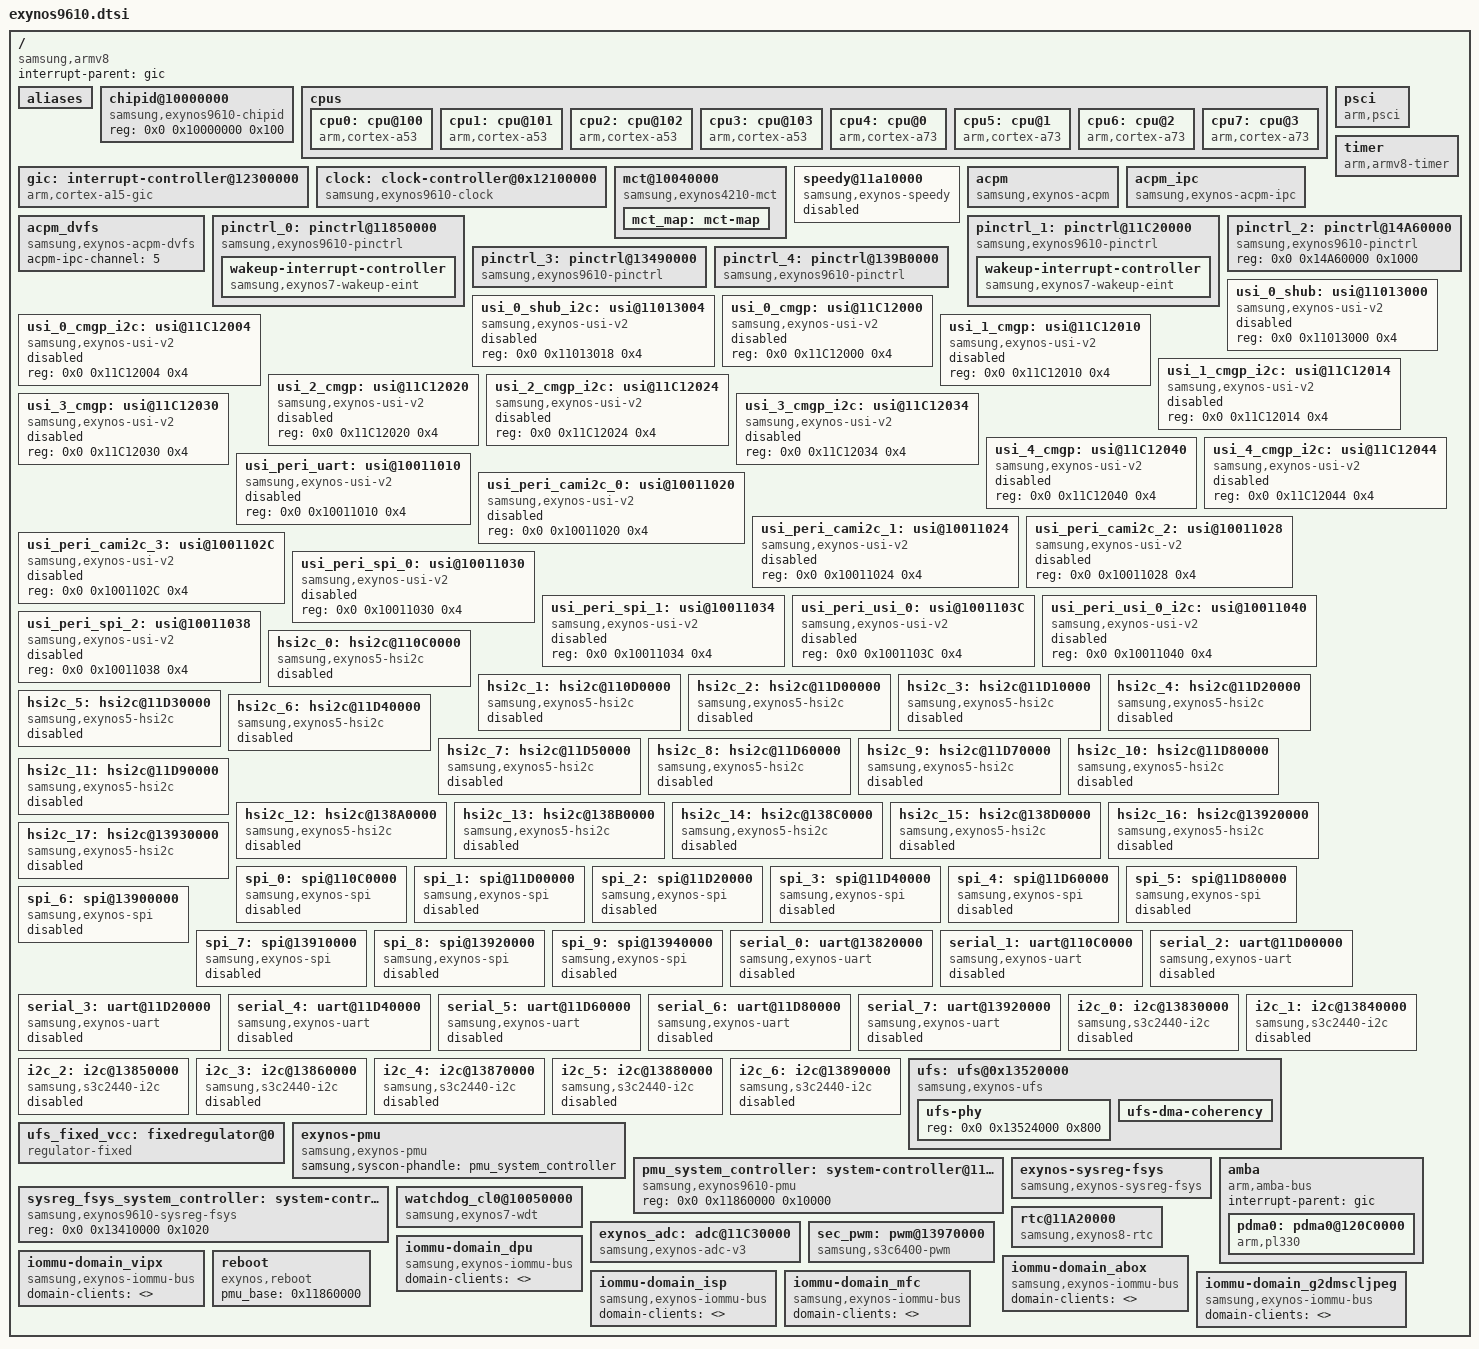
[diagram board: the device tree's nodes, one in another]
/*
 * SAMSUNG EXYNOS9610 SoC device tree source
 *
 * Copyright (c) 2017 Samsung Electronics Co., Ltd.
 *		http://www.samsung.com
 *
 * SAMSUNG EXYNOS9610 SoC device nodes are listed in this file.
 * EXYNOS9610 based board files can include this file and provide
 * values for board specfic bindings.
 *
 * This program is free software; you can redistribute it and/or modify
 * it under the terms of the GNU General Public License version 2 as
 * published by the Free Software Foundation.
 */

#include <dt-bindings/clock/exynos9610.h>
#include <dt-bindings/interrupt-controller/arm-gic.h>
#include "exynos9610-pinctrl.dtsi"
#include <dt-bindings/ufs/ufs.h>
#include "exynos9610-sysmmu.dtsi"

/ {
	compatible = "samsung,armv8", "samsung,exynos9610";
	interrupt-parent = <&gic>;
	#address-cells = <2>;
	#size-cells = <1>;

	aliases {
		pinctrl0 = &pinctrl_0;
		pinctrl1 = &pinctrl_1;
		pinctrl2 = &pinctrl_2;
		pinctrl3 = &pinctrl_3;
		pinctrl4 = &pinctrl_4;
//		pinctrl5 = &pinctrl_5;
		usi0 = &usi_0_shub;
		usi1 = &usi_0_shub_i2c;
		usi2 = &usi_0_cmgp;
		usi3 = &usi_0_cmgp_i2c;
		usi4 = &usi_1_cmgp;
		usi5 = &usi_1_cmgp_i2c;
		usi6 = &usi_2_cmgp;
		usi7 = &usi_2_cmgp_i2c;
		usi8 = &usi_3_cmgp;
		usi9 = &usi_3_cmgp_i2c;
		usi10 = &usi_4_cmgp;
		usi11 = &usi_4_cmgp_i2c;
		usi12 = &usi_peri_uart;
		usi13 = &usi_peri_cami2c_0;
		usi14 = &usi_peri_cami2c_1;
		usi15 = &usi_peri_cami2c_2;
		usi16 = &usi_peri_cami2c_3;
		usi17 = &usi_peri_spi_0;
		usi18 = &usi_peri_spi_1;
		usi19 = &usi_peri_usi_0;
		usi20 = &usi_peri_usi_0_i2c;
		usi21 = &usi_peri_spi_2;
		hsi2c0 = &hsi2c_0;
		hsi2c1 = &hsi2c_1;
		hsi2c2 = &hsi2c_2;
		hsi2c3 = &hsi2c_3;
		hsi2c4 = &hsi2c_4;
		hsi2c5 = &hsi2c_5;
		hsi2c6 = &hsi2c_6;
		hsi2c7 = &hsi2c_7;
		hsi2c8 = &hsi2c_8;
		hsi2c9 = &hsi2c_9;
		hsi2c10 = &hsi2c_10;
		hsi2c11 = &hsi2c_11;
		hsi2c12 = &hsi2c_12;
		hsi2c13 = &hsi2c_13;
		hsi2c14 = &hsi2c_14;
		hsi2c15 = &hsi2c_15;
		hsi2c16 = &hsi2c_16;
		hsi2c17 = &hsi2c_17;
		spi0 = &spi_0;
		spi1 = &spi_1;
		spi2 = &spi_2;
		spi3 = &spi_3;
		spi4 = &spi_4;
		spi5 = &spi_5;
		spi6 = &spi_6;
		spi7 = &spi_7;
		spi8 = &spi_8;
		spi9 = &spi_9;
		uart0 = &serial_0;
		uart1 = &serial_1;
		uart2 = &serial_2;
		uart3 = &serial_3;
		uart4 = &serial_4;
		uart5 = &serial_5;
		uart6 = &serial_6;
		uart7 = &serial_7;
	};

	chipid@10000000 {
		compatible = "samsung,exynos9610-chipid";
		reg = <0x0 0x10000000 0x100>;
	};

	cpus {
		#address-cells = <2>;
		#size-cells = <0>;

		cpu0: cpu@100 {
			device_type = "cpu";
			compatible = "arm,cortex-a53", "arm,armv8";
			reg = <0x0 0x0>;
			enable-method = "psci";
		};
		cpu1: cpu@101 {
			device_type = "cpu";
			compatible = "arm,cortex-a53", "arm,armv8";
			reg = <0x0 0x1>;
			enable-method = "psci";
		};
		cpu2: cpu@102 {
			device_type = "cpu";
			compatible = "arm,cortex-a53", "arm,armv8";
			reg = <0x0 0x2>;
			enable-method = "psci";
		};
		cpu3: cpu@103 {
			device_type = "cpu";
			compatible = "arm,cortex-a53", "arm,armv8";
			reg = <0x0 0x3>;
			enable-method = "psci";
		};
		cpu4: cpu@0 {
			device_type = "cpu";
			compatible = "arm,cortex-a73", "arm,armv8";
			reg = <0x0 0x100>;
			enable-method = "psci";
		};
		cpu5: cpu@1 {
			device_type = "cpu";
			compatible = "arm,cortex-a73", "arm,armv8";
			reg = <0x0 0x101>;
			enable-method = "psci";
		};
		cpu6: cpu@2 {
			device_type = "cpu";
			compatible = "arm,cortex-a73", "arm,armv8";
			reg = <0x0 0x102>;
			enable-method = "psci";
		};
		cpu7: cpu@3 {
			device_type = "cpu";
			compatible = "arm,cortex-a73", "arm,armv8";
			reg = <0x0 0x103>;
			enable-method = "psci";
		};
	};

	psci {
		compatible = "arm,psci";
		method = "smc";
		cpu_suspend = <0xC4000001>;
		cpu_off = <0x84000002>;
		cpu_on = <0xC4000003>;
	};

	gic:interrupt-controller@12300000 {
		compatible = "arm,cortex-a15-gic", "arm,cortex-a9-gic";
		#interrupt-cells = <3>;
		#address-cells = <0>;
		interrupt-controller;
		reg =	<0x0 0x12301000 0x1000>,
			<0x0 0x12302000 0x1000>,
			<0x0 0x12304000 0x2000>,
			<0x0 0x12306000 0x2000>;
		interrupts = <1 9 0xf04>;
	};

	timer {
		compatible = "arm,armv8-timer";
		interrupts = <GIC_PPI 13
				(GIC_CPU_MASK_SIMPLE(8) | IRQ_TYPE_LEVEL_LOW)>,
			     <GIC_PPI 14
				(GIC_CPU_MASK_SIMPLE(8) | IRQ_TYPE_LEVEL_LOW)>,
			     <GIC_PPI 11
				(GIC_CPU_MASK_SIMPLE(8) | IRQ_TYPE_LEVEL_LOW)>,
			     <GIC_PPI 10
				(GIC_CPU_MASK_SIMPLE(8) | IRQ_TYPE_LEVEL_LOW)>;
	        clock-frequency = <26000000>;
		use-clocksource-only;
		use-physical-timer;
	};

	clock: clock-controller@0x12100000 {
		compatible = "samsung,exynos9610-clock";
		reg = <0x0 0x12100000 0x8000>;
		#clock-cells = <1>;
		acpm-ipc-channel = <0>;
	};

	mct@10040000 {
		compatible = "samsung,exynos4210-mct";
		reg = <0x0 0x10040000 0x800>;
		interrupt-controller;
		#interrupt-cells = <1>;
		interrupt-parent = <&mct_map>;
		interrupts =	<0>, <1>, <2>, <3>,
				<4>, <5>, <6>, <7>,
				<8>, <9>, <10>, <11>;
		clocks = <&clock OSCCLK>, <&clock GATE_MCT_QCH>;
		clock-names = "fin_pll", "mct";
		use-clockevent-only;

		mct_map: mct-map {
			#interrupt-cells = <1>;
			#address-cells = <0>;
			#size-cells = <0>;
			interrupt-map = <0 &gic 0 234 0>,
					<1 &gic 0 235 0>,
					<2 &gic 0 236 0>,
					<3 &gic 0 237 0>,
					<4 &gic 0 238 0>,
					<5 &gic 0 239 0>,
					<6 &gic 0 240 0>,
					<7 &gic 0 241 0>,
					<8 &gic 0 242 0>,
					<9 &gic 0 243 0>,
					<10 &gic 0 244 0>,
					<11 &gic 0 245 0>;
		};
	};

	speedy@11a10000 {
		compatible = "samsung,exynos-speedy";
		reg = <0x0 0x11a10000 0x2000>;
		interrupts = <0 37 0>;
		#address-cells = <1>;
		#size-cells = <0>;
		pinctrl-names = "default";
		pinctrl-0 = <&speedy_bus>;
		status = "disabled";
	};

	acpm {
		compatible = "samsung,exynos-acpm";
		#address-cells = <2>;
		#size-cells = <1>;
		acpm-ipc-channel = <4>;
		fvmap_offset = <0x6000>;
		reg = <0x0 0x11820000 0x1000>;          /* TIMER_APM */
		reg-names = "timer_apm";
		peritimer-cnt = <0xFFFF>;
	};

	acpm_ipc {
		compatible = "samsung,exynos-acpm-ipc";
		#address-cells = <2>;
		#size-cells = <1>;
		interrupts = <0 38 0>;                  /* AP2APM MAILBOX SPI NUM*/
		reg = <0x0 0x11900000 0x1000>,          /* AP2APM MAILBOX */
		    <0x0 0x2039000 0x15000>;        /* APM SRAM */
		initdata-base = <0x6F00>;
		num-timestamps = <32>;
		debug-log-level = <0>;
		logging-period = <500>;
		dump-base = <0x203C000>;
		dump-size = <0x12000>;                  /* 72KB */
	};

	acpm_dvfs {
		compatible = "samsung,exynos-acpm-dvfs";
		acpm-ipc-channel = <5>;
	};

	/* ALIVE */
	pinctrl_0: pinctrl@11850000 {
		compatible = "samsung,exynos9610-pinctrl";
		reg = <0x0 0x11850000 0x1000>;
		interrupts = <0 0 0>, <0 1 0>, <0 2 0>, <0 3 0>,
				<0 4 0>, <0 5 0>, <0 6 0>, <0 7 0>,
				<0 8 0>, <0 9 0>, <0 10 0>, <0 11 0>,
				<0 12 0>, <0 13 0>, <0 14 0>, <0 15 0>,
				<0 16 0>, <0 17 0>, <0 18 0>, <0 19 0>,
				<0 20 0>, <0 21 0>, <0 22 0>, <0 23 0>;

		wakeup-interrupt-controller {
			compatible = "samsung,exynos7-wakeup-eint";
		};
	};

	/* CMGP */
	pinctrl_1: pinctrl@11C20000{
		compatible = "samsung,exynos9610-pinctrl";
		reg = <0x0 0x11C20000 0x1000>;
		interrupts = <0 142 0>, <0 143 0>, <0 144 0>, <0 145 0>,
				<0 158 0>, <0 159 0>, <0 160 0>, <0 161 0>,
				<0 162 0>, <0 170 0>, <0 171 0>, <0 172 0>,
				<0 173 0>, <0 174 0>, <0 185 0>, <0 196 0>,
				<0 197 0>, <0 226 0>, <0 227 0>, <0 228 0>,
				<0 269 0>, <0 270 0>, <0 272 0>, <0 278 0>,
				<0 318 0>, <0 319 0>;

		wakeup-interrupt-controller {
			compatible = "samsung,exynos7-wakeup-eint";
		};
	};

	/* DISPAUD */
	pinctrl_2: pinctrl@14A60000{
		compatible = "samsung,exynos9610-pinctrl";
		reg = <0x0 0x14A60000 0x1000>;
	};

	/* FSYS */
	pinctrl_3: pinctrl@13490000 {
		compatible = "samsung,exynos9610-pinctrl";
		reg = <0x0 0x13490000 0x1000>;
		interrupts = <0 150 0>;
	};

	/* TOP */
	pinctrl_4: pinctrl@139B0000 {
		compatible = "samsung,exynos9610-pinctrl";
		reg = <0x0 0x139B0000 0x1000>;
		interrupts = <0 266 0>;
	};

#if 0
	/* SHUB */
	pinctrl_5: pinctrl@11080000{
		compatible = "samsung,exynos9610-pinctrl";
		reg = <0x0 0x11080000 0x1000>;
		interrupts = <0 116 0>;
	};
#endif

	/* USI_SHUB_0 */
	usi_0_shub: usi@11013000 {
		compatible = "samsung,exynos-usi-v2";
		reg = <0x0 0x11013000 0x4>;
		/*	usi_v2_mode = "i2c" or "spi" or "uart"	*/
		status = "disabled";
	};

	/* USI_SHUB_0_I2C */
	usi_0_shub_i2c: usi@11013004 {
		compatible = "samsung,exynos-usi-v2";
		reg = <0x0 0x11013018 0x4>;
		/*	usi_v2_mode = "i2c" or "spi" or "uart"	*/
		status = "disabled";
	};

	/* USI_0_CMGP */
	usi_0_cmgp: usi@11C12000 {
		compatible = "samsung,exynos-usi-v2";
		reg = <0x0 0x11C12000 0x4>;
		/*	usi_v2_mode = "i2c" or "spi" or "uart"	*/
		status = "disabled";
	};

	/* USI_0_CMGP_I2C */
	usi_0_cmgp_i2c: usi@11C12004 {
		compatible = "samsung,exynos-usi-v2";
		reg = <0x0 0x11C12004 0x4>;
		/*	usi_v2_mode = "i2c" or "spi" or "uart"	*/
		status = "disabled";
	};

	/* USI_1_CMGP */
	usi_1_cmgp: usi@11C12010 {
		compatible = "samsung,exynos-usi-v2";
		reg = <0x0 0x11C12010 0x4>;
		/*	usi_v2_mode = "i2c" or "spi" or "uart"	*/
		status = "disabled";
	};

	/* USI_1_CMGP_I2C */
	usi_1_cmgp_i2c: usi@11C12014 {
		compatible = "samsung,exynos-usi-v2";
		reg = <0x0 0x11C12014 0x4>;
		/*	usi_v2_mode = "i2c" or "spi" or "uart"	*/
		status = "disabled";
	};

	/* USI_2_CMGP */
	usi_2_cmgp: usi@11C12020 {
		compatible = "samsung,exynos-usi-v2";
		reg = <0x0 0x11C12020 0x4>;
		/*	usi_v2_mode = "i2c" or "spi" or "uart"	*/
		status = "disabled";
	};

	/* USI_2_CMGP_I2C */
	usi_2_cmgp_i2c: usi@11C12024 {
		compatible = "samsung,exynos-usi-v2";
		reg = <0x0 0x11C12024 0x4>;
		/*	usi_v2_mode = "i2c" or "spi" or "uart"	*/
		status = "disabled";
	};

	/* USI_3_CMGP */
	usi_3_cmgp: usi@11C12030 {
		compatible = "samsung,exynos-usi-v2";
		reg = <0x0 0x11C12030 0x4>;
		/*	usi_v2_mode = "i2c" or "spi" or "uart"	*/
		status = "disabled";
	};

	/* USI_3_CMGP_I2C */
	usi_3_cmgp_i2c: usi@11C12034 {
		compatible = "samsung,exynos-usi-v2";
		reg = <0x0 0x11C12034 0x4>;
		/*	usi_v2_mode = "i2c" or "spi" or "uart"	*/
		status = "disabled";
	};

	/* USI_4_CMGP */
	usi_4_cmgp: usi@11C12040 {
		compatible = "samsung,exynos-usi-v2";
		reg = <0x0 0x11C12040 0x4>;
		/*	usi_v2_mode = "i2c" or "spi" or "uart"	*/
		status = "disabled";
	};

	/* USI_4_CMGP_I2C */
	usi_4_cmgp_i2c: usi@11C12044 {
		compatible = "samsung,exynos-usi-v2";
		reg = <0x0 0x11C12044 0x4>;
		/*	usi_v2_mode = "i2c" or "spi" or "uart"	*/
		status = "disabled";
	};

	/* USI_PERI_UART */
	usi_peri_uart: usi@10011010 {
		compatible = "samsung,exynos-usi-v2";
		reg = <0x0 0x10011010 0x4>;
		/*	usi_v2_mode = "i2c" or "spi" or "uart"	*/
		status = "disabled";
	};

	/* USI_PERI_CAMI2C_0 */
	usi_peri_cami2c_0: usi@10011020 {
		compatible = "samsung,exynos-usi-v2";
		reg = <0x0 0x10011020 0x4>;
		/*	usi_v2_mode = "i2c" or "spi" or "uart"	*/
		status = "disabled";
	};

	/* USI_PERI_CAMI2C_1 */
	usi_peri_cami2c_1: usi@10011024 {
		compatible = "samsung,exynos-usi-v2";
		reg = <0x0 0x10011024 0x4>;
		/*	usi_v2_mode = "i2c" or "spi" or "uart"	*/
		status = "disabled";
	};

	/* USI_PERI_CAMI2C_2 */
	usi_peri_cami2c_2: usi@10011028 {
		compatible = "samsung,exynos-usi-v2";
		reg = <0x0 0x10011028 0x4>;
		/*	usi_v2_mode = "i2c" or "spi" or "uart"	*/
		status = "disabled";
	};

	/* USI_PERI_CAMI2C_3 */
	usi_peri_cami2c_3: usi@1001102C {
		compatible = "samsung,exynos-usi-v2";
		reg = <0x0 0x1001102C 0x4>;
		/*	usi_v2_mode = "i2c" or "spi" or "uart"	*/
		status = "disabled";
	};

	/* USI_PERI_SPI_0 */
	usi_peri_spi_0: usi@10011030 {
		compatible = "samsung,exynos-usi-v2";
		reg = <0x0 0x10011030 0x4>;
		/*	usi_v2_mode = "i2c" or "spi" or "uart"	*/
		status = "disabled";
	};

	/* USI_PERI_SPI_1 */
	usi_peri_spi_1: usi@10011034 {
		compatible = "samsung,exynos-usi-v2";
		reg = <0x0 0x10011034 0x4>;
		/*	usi_v2_mode = "i2c" or "spi" or "uart"	*/
		status = "disabled";
	};

	/* USI_PERI_USI_0 */
	usi_peri_usi_0: usi@1001103C {
		compatible = "samsung,exynos-usi-v2";
		reg = <0x0 0x1001103C 0x4>;
		/*	usi_v2_mode = "i2c" or "spi" or "uart"	*/
		status = "disabled";
	};

	/* USI_PERI_USI_0_I2C */
	usi_peri_usi_0_i2c: usi@10011040 {
		compatible = "samsung,exynos-usi-v2";
		reg = <0x0 0x10011040 0x4>;
		/*	usi_v2_mode = "i2c" or "spi" or "uart"	*/
		status = "disabled";
	};

	/* USI_PERI_SPI_2 */
	usi_peri_spi_2: usi@10011038 {
		compatible = "samsung,exynos-usi-v2";
		reg = <0x0 0x10011038 0x4>;
		/*	usi_v2_mode = "i2c" or "spi" or "uart"	*/
		status = "disabled";
	};

	/* USI_0_SHUB */
	hsi2c_0: hsi2c@110C0000 {
		compatible = "samsung,exynos5-hsi2c";
		samsung,check-transdone-int;
		default-clk = <200000000>;
		reg = <0x0 0x110C0000 0x1000>;
		interrupts = <0 112 0>;
		#address-cells = <1>;
		#size-cells = <0>;
		pinctrl-names = "default";
		pinctrl-0 = <&hsi2c0_bus>;
		clocks = <&clock MUX_SHUB_USI00>, <&clock GATE_USI_SHUB00_QCH>;
		clock-names = "ipclk_hsi2c", "gate_hsi2c_clk";
		samsung,scl-clk-stretching;
		samsung,usi-i2c-v2;
		gpio_scl= <&gph0 0 0x1>;
		gpio_sda= <&gph0 1 0x1>;
		status = "disabled";
	};

	/* USI_0_SHUB_I2C */
	hsi2c_1: hsi2c@110D0000 {
		compatible = "samsung,exynos5-hsi2c";
		samsung,check-transdone-int;
		default-clk = <200000000>;
		reg = <0x0 0x110D0000 0x1000>;
		interrupts = <0 117 0>;
		#address-cells = <1>;
		#size-cells = <0>;
		pinctrl-names = "default";
		pinctrl-0 = <&hsi2c1_bus>;
		clocks = <&clock MUX_SHUB_I2C>, <&clock GATE_I2C_SHUB00_QCH>;
		clock-names = "ipclk_hsi2c", "gate_hsi2c_clk";
		samsung,scl-clk-stretching;
		samsung,usi-i2c-v2;
		gpio_scl= <&gph0 2 0x1>;
		gpio_sda= <&gph0 3 0x1>;
		status = "disabled";
	};

	/* USI_0_CMGP */
	hsi2c_2: hsi2c@11D00000 {
		compatible = "samsung,exynos5-hsi2c";
		samsung,check-transdone-int;
		default-clk = <200000000>;
		reg = <0x0 0x11D00000 0x1000>;
		interrupts = <0 311 0>;
		#address-cells = <1>;
		#size-cells = <0>;
		pinctrl-names = "default";
		pinctrl-0 = <&hsi2c2_bus>;
		clocks = <&clock CMGP00_USI>, <&clock GATE_USI_CMGP00_QCH>;
		clock-names = "ipclk_hsi2c", "gate_hsi2c_clk";
		samsung,scl-clk-stretching;
		samsung,usi-i2c-v2;
		gpio_scl= <&gpm0 0 0x1>;
		gpio_sda= <&gpm1 0 0x1>;
		status = "disabled";
	};

	/* USI_0_CMGP_I2C */
	hsi2c_3: hsi2c@11D10000 {
		compatible = "samsung,exynos5-hsi2c";
		samsung,check-transdone-int;
		default-clk = <200000000>;
		reg = <0x0 0x11D10000 0x1000>;
		interrupts = <0 273 0>;
		#address-cells = <1>;
		#size-cells = <0>;
		pinctrl-names = "default";
		pinctrl-0 = <&hsi2c3_bus>;
		clocks = <&clock CMGP_I2C>, <&clock GATE_I2C_CMGP00_QCH>;
		clock-names = "ipclk_hsi2c", "gate_hsi2c_clk";
		samsung,scl-clk-stretching;
		samsung,usi-i2c-v2;
		gpio_scl= <&gpm2 0 0x1>;
		gpio_sda= <&gpm3 0 0x1>;
		status = "disabled";
	};

	/* USI_1_CMGP */
	hsi2c_4: hsi2c@11D20000 {
		compatible = "samsung,exynos5-hsi2c";
		samsung,check-transdone-int;
		default-clk = <200000000>;
		reg = <0x0 0x11D20000 0x1000>;
		interrupts = <0 312 0>;
		#address-cells = <1>;
		#size-cells = <0>;
		pinctrl-names = "default";
		pinctrl-0 = <&hsi2c4_bus>;
		clocks = <&clock CMGP01_USI>, <&clock GATE_USI_CMGP01_QCH>;
		clock-names = "ipclk_hsi2c", "gate_hsi2c_clk";
		samsung,scl-clk-stretching;
		samsung,usi-i2c-v2;
		gpio_scl= <&gpm4 0 0x1>;
		gpio_sda= <&gpm5 0 0x1>;
		status = "disabled";
	};

	/* USI_1_CMGP_I2C */
	hsi2c_5: hsi2c@11D30000 {
		compatible = "samsung,exynos5-hsi2c";
		samsung,check-transdone-int;
		default-clk = <200000000>;
		reg = <0x0 0x11D30000 0x1000>;
		interrupts = <0 274 0>;
		#address-cells = <1>;
		#size-cells = <0>;
		pinctrl-names = "default";
		pinctrl-0 = <&hsi2c5_bus>;
		clocks = <&clock CMGP_I2C>, <&clock GATE_I2C_CMGP01_QCH>;
		clock-names = "ipclk_hsi2c", "gate_hsi2c_clk";
		samsung,scl-clk-stretching;
		samsung,usi-i2c-v2;
		gpio_scl= <&gpm6 0 0x1>;
		gpio_sda= <&gpm7 0 0x1>;
		status = "disabled";
	};

	/* USI_2_CMGP */
	hsi2c_6: hsi2c@11D40000 {
		compatible = "samsung,exynos5-hsi2c";
		samsung,check-transdone-int;
		default-clk = <200000000>;
		reg = <0x0 0x11D40000 0x1000>;
		interrupts = <0 313 0>;
		#address-cells = <1>;
		#size-cells = <0>;
		pinctrl-names = "default";
		pinctrl-0 = <&hsi2c6_bus>;
		clocks = <&clock CMGP02_USI>, <&clock GATE_USI_CMGP02_QCH>;
		clock-names = "ipclk_hsi2c", "gate_hsi2c_clk";
		samsung,scl-clk-stretching;
		samsung,usi-i2c-v2;
		gpio_scl= <&gpm8 0 0x1>;
		gpio_sda= <&gpm9 0 0x1>;
		status = "disabled";
	};

	/* USI_2_CMGP_I2C */
	hsi2c_7: hsi2c@11D50000 {
		compatible = "samsung,exynos5-hsi2c";
		samsung,check-transdone-int;
		default-clk = <200000000>;
		reg = <0x0 0x11D50000 0x1000>;
		interrupts = <0 275 0>;
		#address-cells = <1>;
		#size-cells = <0>;
		pinctrl-names = "default";
		pinctrl-0 = <&hsi2c7_bus>;
		clocks = <&clock CMGP_I2C>, <&clock GATE_I2C_CMGP02_QCH>;
		clock-names = "ipclk_hsi2c", "gate_hsi2c_clk";
		samsung,scl-clk-stretching;
		samsung,usi-i2c-v2;
		gpio_scl= <&gpm10 0 0x1>;
		gpio_sda= <&gpm11 0 0x1>;
		status = "disabled";
	};

	/* USI_3_CMGP */
	hsi2c_8: hsi2c@11D60000 {
		compatible = "samsung,exynos5-hsi2c";
		samsung,check-transdone-int;
		default-clk = <200000000>;
		reg = <0x0 0x11D60000 0x1000>;
		interrupts = <0 314 0>;
		#address-cells = <1>;
		#size-cells = <0>;
		pinctrl-names = "default";
		pinctrl-0 = <&hsi2c8_bus>;
		clocks = <&clock CMGP03_USI>, <&clock GATE_USI_CMGP03_QCH>;
		clock-names = "ipclk_hsi2c", "gate_hsi2c_clk";
		samsung,scl-clk-stretching;
		samsung,usi-i2c-v2;
		gpio_scl= <&gpm12 0 0x1>;
		gpio_sda= <&gpm13 0 0x1>;
		status = "disabled";
	};

	/* USI_3_CMGP_I2C */
	hsi2c_9: hsi2c@11D70000 {
		compatible = "samsung,exynos5-hsi2c";
		samsung,check-transdone-int;
		default-clk = <200000000>;
		reg = <0x0 0x11D70000 0x1000>;
		interrupts = <0 276 0>;
		#address-cells = <1>;
		#size-cells = <0>;
		pinctrl-names = "default";
		pinctrl-0 = <&hsi2c9_bus>;
		clocks = <&clock CMGP_I2C>, <&clock GATE_I2C_CMGP03_QCH>;
		clock-names = "ipclk_hsi2c", "gate_hsi2c_clk";
		samsung,scl-clk-stretching;
		samsung,usi-i2c-v2;
		gpio_scl= <&gpm14 0 0x1>;
		gpio_sda= <&gpm15 0 0x1>;
		status = "disabled";
	};

	/* USI_4_CMGP */
	hsi2c_10: hsi2c@11D80000 {
		compatible = "samsung,exynos5-hsi2c";
		samsung,check-transdone-int;
		default-clk = <200000000>;
		reg = <0x0 0x11D80000 0x1000>;
		interrupts = <0 315 0>;
		#address-cells = <1>;
		#size-cells = <0>;
		pinctrl-names = "default";
		pinctrl-0 = <&hsi2c10_bus>;
		clocks = <&clock CMGP04_USI>, <&clock GATE_USI_CMGP04_QCH>;
		clock-names = "ipclk_hsi2c", "gate_hsi2c_clk";
		samsung,scl-clk-stretching;
		samsung,usi-i2c-v2;
		gpio_scl= <&gpm16 0 0x1>;
		gpio_sda= <&gpm17 0 0x1>;
		status = "disabled";
	};

	/* USI_4_CMGP_I2C */
	hsi2c_11: hsi2c@11D90000 {
		compatible = "samsung,exynos5-hsi2c";
		samsung,check-transdone-int;
		default-clk = <200000000>;
		reg = <0x0 0x11D90000 0x1000>;
		interrupts = <0 277 0>;
		#address-cells = <1>;
		#size-cells = <0>;
		pinctrl-names = "default";
		pinctrl-0 = <&hsi2c11_bus>;
		clocks = <&clock CMGP_I2C>, <&clock GATE_I2C_CMGP04_QCH>;
		clock-names = "ipclk_hsi2c", "gate_hsi2c_clk";
		samsung,scl-clk-stretching;
		samsung,usi-i2c-v2;
		gpio_scl= <&gpm18 0 0x1>;
		gpio_sda= <&gpm19 0 0x1>;
		status = "disabled";
	};

	/* USI_PERI_CAMI2C_0 */
	hsi2c_12: hsi2c@138A0000 {
		compatible = "samsung,exynos5-hsi2c";
		samsung,check-transdone-int;
		default-clk = <200000000>;
		reg = <0x0 0x138A0000 0x1000>;
		interrupts = <0 257 0>;
		#address-cells = <1>;
		#size-cells = <0>;
		pinctrl-names = "default";
		pinctrl-0 = <&hsi2c12_bus>;
		clocks = <&clock I2C>, <&clock GATE_CAMI2C_0_QCH>;
		clock-names = "ipclk_hsi2c", "gate_hsi2c_clk";
		samsung,scl-clk-stretching;
		samsung,usi-i2c-v2;
		gpio_scl= <&gpc0 1 0x1>;
		gpio_sda= <&gpc0 0 0x1>;
		status = "disabled";
	};

	/* USI_PERI_CAMI2C_1 */
	hsi2c_13: hsi2c@138B0000 {
		compatible = "samsung,exynos5-hsi2c";
		samsung,check-transdone-int;
		default-clk = <200000000>;
		reg = <0x0 0x138B0000 0x1000>;
		interrupts = <0 258 0>;
		#address-cells = <1>;
		#size-cells = <0>;
		pinctrl-names = "default";
		pinctrl-0 = <&hsi2c13_bus>;
		clocks = <&clock I2C>, <&clock GATE_CAMI2C_1_QCH>;
		clock-names = "ipclk_hsi2c", "gate_hsi2c_clk";
		samsung,scl-clk-stretching;
		samsung,usi-i2c-v2;
		gpio_scl= <&gpc0 3 0x1>;
		gpio_sda= <&gpc0 2 0x1>;
		status = "disabled";
	};

	/* USI_PERI_CAMI2C_2 */
	hsi2c_14: hsi2c@138C0000 {
		compatible = "samsung,exynos5-hsi2c";
		samsung,check-transdone-int;
		default-clk = <200000000>;
		reg = <0x0 0x138C0000 0x1000>;
		interrupts = <0 259 0>;
		#address-cells = <1>;
		#size-cells = <0>;
		pinctrl-names = "default";
		pinctrl-0 = <&hsi2c14_bus>;
		clocks = <&clock I2C>, <&clock GATE_CAMI2C_2_QCH>;
		clock-names = "ipclk_hsi2c", "gate_hsi2c_clk";
		samsung,scl-clk-stretching;
		samsung,usi-i2c-v2;
		gpio_scl= <&gpc0 5 0x1>;
		gpio_sda= <&gpc0 4 0x1>;
		status = "disabled";
	};

	/* USI_PERI_CAMI2C_3 */
	hsi2c_15: hsi2c@138D0000 {
		compatible = "samsung,exynos5-hsi2c";
		samsung,check-transdone-int;
		default-clk = <200000000>;
		reg = <0x0 0x138D0000 0x1000>;
		interrupts = <0 260 0>;
		#address-cells = <1>;
		#size-cells = <0>;
		pinctrl-names = "default";
		pinctrl-0 = <&hsi2c15_bus>;
		clocks = <&clock I2C>, <&clock GATE_CAMI2C_3_QCH>;
		clock-names = "ipclk_hsi2c", "gate_hsi2c_clk";
		samsung,scl-clk-stretching;
		samsung,usi-i2c-v2;
		gpio_scl= <&gpc0 7 0x1>;
		gpio_sda= <&gpc0 6 0x1>;
		status = "disabled";
	};

	/* USI_PERI_USI_0 */
	hsi2c_16: hsi2c@13920000 {
		compatible = "samsung,exynos5-hsi2c";
		samsung,check-transdone-int;
		default-clk = <200000000>;
		reg = <0x0 0x13920000 0x1000>;
		interrupts = <0 267 0>;
		#address-cells = <1>;
		#size-cells = <0>;
		pinctrl-names = "default";
		pinctrl-0 = <&hsi2c16_bus>;
		clocks = <&clock USI_USI>, <&clock GATE_USI00_USI_QCH>;
		clock-names = "ipclk_hsi2c", "gate_hsi2c_clk";
		samsung,scl-clk-stretching;
		samsung,usi-i2c-v2;
		gpio_scl= <&gpc1 0 0x1>;
		gpio_sda= <&gpc1 1 0x1>;
		status = "disabled";
	};

	/* USI_PERI_USI_0_I2C */
	hsi2c_17: hsi2c@13930000 {
		compatible = "samsung,exynos5-hsi2c";
		samsung,check-transdone-int;
		default-clk = <200000000>;
		reg = <0x0 0x13930000 0x1000>;
		interrupts = <0 268 0>;
		#address-cells = <1>;
		#size-cells = <0>;
		pinctrl-names = "default";
		pinctrl-0 = <&hsi2c17_bus>;
		clocks = <&clock USI_I2C>, <&clock GATE_USI00_I2C_QCH>;
		clock-names = "ipclk_hsi2c", "gate_hsi2c_clk";
		samsung,scl-clk-stretching;
		samsung,usi-i2c-v2;
		gpio_scl= <&gpc1 2 0x1>;
		gpio_sda= <&gpc1 3 0x1>;
		status = "disabled";
	};

	/* USI_0_SHUB */
	spi_0: spi@110C0000 {
		compatible = "samsung,exynos-spi";
		reg = <0x0 0x110C0000 0x100>;
		samsung,spi-fifosize = <64>;
		interrupts = <0 112 0>;
/*
		dma-mode;
		dmas = <&pdma0 25 &pdma0 24>;
*/
		dma-names = "tx", "rx";
		swap-mode;
		#address-cells = <1>;
		#size-cells = <0>;
		clocks = <&clock GATE_USI_SHUB00_QCH>, <&clock MUX_SHUB_USI00>;
		clock-names = "gate_spi_clk", "ipclk_spi0";
		pinctrl-names = "default";
		pinctrl-0 = <&spi0_bus>;
		status = "disabled";
	};

	/* USI_0_CMGP */
	spi_1: spi@11D00000 {
		compatible = "samsung,exynos-spi";
		reg = <0x0 0x11D00000 0x100>;
		samsung,spi-fifosize = <64>;
		interrupts = <0 311 0>;
/*
		dma-mode;
		dmas = <&pdma0 25 &pdma0 24>;
*/
		dma-names = "tx", "rx";
		swap-mode;
		#address-cells = <1>;
		#size-cells = <0>;
		clocks = <&clock GATE_USI_CMGP00_QCH>, <&clock CMGP00_USI>;
		clock-names = "gate_spi_clk", "ipclk_spi0";
		pinctrl-names = "default";
		pinctrl-0 = <&spi1_bus>;
		status = "disabled";
	};

	/* USI_1_CMGP */
	spi_2: spi@11D20000 {
		compatible = "samsung,exynos-spi";
		reg = <0x0 0x11D20000 0x100>;
		samsung,spi-fifosize = <64>;
		interrupts = <0 312 0>;
/*
		dma-mode;
		dmas = <&pdma0 25 &pdma0 24>;
*/
		dma-names = "tx", "rx";
		swap-mode;
		#address-cells = <1>;
		#size-cells = <0>;
		clocks = <&clock GATE_USI_CMGP01_QCH>, <&clock CMGP01_USI>;
		clock-names = "gate_spi_clk", "ipclk_spi0";
		pinctrl-names = "default";
		pinctrl-0 = <&spi2_bus>;
		status = "disabled";
	};

	/* USI_2_CMGP */
	spi_3: spi@11D40000 {
		compatible = "samsung,exynos-spi";
		reg = <0x0 0x11D40000 0x100>;
		samsung,spi-fifosize = <64>;
		interrupts = <0 313 0>;
/*
		dma-mode;
		dmas = <&pdma0 25 &pdma0 24>;
*/
		dma-names = "tx", "rx";
		swap-mode;
		#address-cells = <1>;
		#size-cells = <0>;
		clocks = <&clock GATE_USI_CMGP02_QCH>, <&clock CMGP02_USI>;
		clock-names = "gate_spi_clk", "ipclk_spi0";
		pinctrl-names = "default";
		pinctrl-0 = <&spi3_bus>;
		status = "disabled";
	};

	/* USI_3_CMGP */
	spi_4: spi@11D60000 {
		compatible = "samsung,exynos-spi";
		reg = <0x0 0x11D60000 0x100>;
		samsung,spi-fifosize = <64>;
		interrupts = <0 314 0>;
/*
		dma-mode;
		dmas = <&pdma0 25 &pdma0 24>;
*/
		dma-names = "tx", "rx";
		swap-mode;
		#address-cells = <1>;
		#size-cells = <0>;
		clocks = <&clock GATE_USI_CMGP03_QCH>, <&clock CMGP03_USI>;
		clock-names = "gate_spi_clk", "ipclk_spi0";
		pinctrl-names = "default";
		pinctrl-0 = <&spi4_bus>;
		status = "disabled";
	};

	/* USI_4_CMGP */
	spi_5: spi@11D80000 {
		compatible = "samsung,exynos-spi";
		reg = <0x0 0x11D80000 0x100>;
		samsung,spi-fifosize = <64>;
		interrupts = <0 315 0>;
/*
		dma-mode;
		dmas = <&pdma0 25 &pdma0 24>;
*/
		dma-names = "tx", "rx";
		swap-mode;
		#address-cells = <1>;
		#size-cells = <0>;
		clocks = <&clock GATE_USI_CMGP04_QCH>, <&clock CMGP04_USI>;
		clock-names = "gate_spi_clk", "ipclk_spi0";
		pinctrl-names = "default";
		pinctrl-0 = <&spi5_bus>;
		status = "disabled";
	};

	/* USI_PERI_SPI_0  */
	spi_6: spi@13900000 {
		compatible = "samsung,exynos-spi";
		reg = <0x0 0x13900000 0x100>;
		samsung,spi-fifosize = <64>;
		interrupts = <0 254 0>;
/*
		dma-mode;
		dmas = <&pdma0 19 &pdma0 18>;
*/
		dma-names = "tx", "rx";
		swap-mode;
		#address-cells = <1>;
		#size-cells = <0>;
		clocks = <&clock GATE_SPI_0_QCH>, <&clock SPI0>;
		clock-names = "gate_spi_clk", "ipclk_spi0";
		pinctrl-names = "default";
		pinctrl-0 = <&spi6_bus>;
		status = "disabled";
	};

	/* USI_PERI_SPI_1  */
	spi_7: spi@13910000 {
		compatible = "samsung,exynos-spi";
		reg = <0x0 0x13910000 0x100>;
		samsung,spi-fifosize = <64>;
		interrupts = <0 255 0>;
/*
		dma-mode;
		dmas = <&pdma0 21 &pdma0 20>;
*/
		dma-names = "tx", "rx";
		swap-mode;
		#address-cells = <1>;
		#size-cells = <0>;
		clocks = <&clock GATE_SPI_1_QCH>, <&clock SPI1>;
		clock-names = "gate_spi_clk", "ipclk_spi0";
		pinctrl-names = "default";
		pinctrl-0 = <&spi7_bus>;
		status = "disabled";
	};

	/* USI_PERI_USI_0 */
	spi_8: spi@13920000 {
		compatible = "samsung,exynos-spi";
		reg = <0x0 0x13920000 0x100>;
		samsung,spi-fifosize = <64>;
		interrupts = <0 267 0>;
/*
		dma-mode;
		dmas = <&pdma0 25 &pdma0 24>;
*/
		dma-names = "tx", "rx";
		swap-mode;
		#address-cells = <1>;
		#size-cells = <0>;
		clocks = <&clock GATE_USI00_USI_QCH>, <&clock USI_USI>;
		clock-names = "gate_spi_clk", "ipclk_spi0";
		pinctrl-names = "default";
		pinctrl-0 = <&spi8_bus>;
		status = "disabled";
	};

	/* SPI USI_PERI_SPI_2 */
	spi_9: spi@13940000 {
		compatible = "samsung,exynos-spi";
		reg = <0x0 0x13940000 0x100>;
		samsung,spi-fifosize = <256>;
		interrupts = <0 256 0>;
/*
		dma-mode;
		dmas = <&pdma0 23 &pdma0 22>;
*/
		dma-names = "tx", "rx";
		swap-mode;
		#address-cells = <1>;
		#size-cells = <0>;
		clocks = <&clock GATE_SPI_2_QCH>, <&clock SPI2>;
		clock-names = "gate_spi_clk", "ipclk_spi0";
		pinctrl-names = "default";
		pinctrl-0 = <&spi9_bus>;
		status = "disabled";
	};

	/* USI_PERI_UART */
	serial_0: uart@13820000 {
		compatible = "samsung,exynos-uart";
		samsung,separate-uart-clk;
		reg = <0x0 0x13820000 0x100>;
		samsung,fifo-size = <256>;
		interrupts = <0 246 0>;
		pinctrl-names = "default";
		pinctrl-0 = <&uart0_bus>; /* or _bus_dual */
		samsung,usi-serial-v2;
		clocks = <&clock GATE_UART_QCH>, <&clock UART>;
		clock-names = "gate_uart_clk0", "ipclk_uart0";
		status = "disabled";
	};

	/* USI_0_SHUB */
	serial_1: uart@110C0000 {
		compatible = "samsung,exynos-uart";
		samsung,separate-uart-clk;
		reg = <0x0 0x110C0000 0x100>;
		samsung,fifo-size = <64>;
		interrupts = <0 112 0>;
		pinctrl-names = "default";
		pinctrl-0 = <&uart1_bus_single>; /* or _bus_dual */
		samsung,usi-serial-v2;
		clocks = <&clock GATE_USI_SHUB00_QCH>, <&clock MUX_SHUB_USI00>;
		clock-names = "gate_uart_clk1", "ipclk_uart1";
		status = "disabled";
	};

	/* USI_0_CMGP */
	serial_2: uart@11D00000 {
		compatible = "samsung,exynos-uart";
		samsung,separate-uart-clk;
		reg = <0x0 0x11D00000 0x100>;
		samsung,fifo-size = <64>;
		interrupts = <0 311 0>;
		pinctrl-names = "default";
		pinctrl-0 = <&uart2_bus_single>; /* or _bus_dual */
		samsung,usi-serial-v2;
		clocks = <&clock GATE_USI_CMGP00_QCH>, <&clock CMGP00_USI>;
		clock-names = "gate_uart_clk2", "ipclk_uart2";
		status = "disabled";
	};

	/* USI_1_CMGP */
	serial_3: uart@11D20000 {
		compatible = "samsung,exynos-uart";
		samsung,separate-uart-clk;
		reg = <0x0 0x11D20000 0x100>;
		samsung,fifo-size = <64>;
		interrupts = <0 312 0>;
		pinctrl-names = "default";
		pinctrl-0 = <&uart3_bus_single>; /* or _bus_dual */
		samsung,usi-serial-v2;
		clocks = <&clock GATE_USI_CMGP01_QCH>, <&clock CMGP01_USI>;
		clock-names = "gate_uart_clk3", "ipclk_uart3";
		status = "disabled";
	};

	/* USI_2_CMGP */
	serial_4: uart@11D40000 {
		compatible = "samsung,exynos-uart";
		samsung,separate-uart-clk;
		reg = <0x0 0x11D40000 0x100>;
		samsung,fifo-size = <64>;
		interrupts = <0 313 0>;
		pinctrl-names = "default";
		pinctrl-0 = <&uart4_bus_single>; /* or _bus_dual */
		samsung,usi-serial-v2;
		clocks = <&clock GATE_USI_CMGP02_QCH>, <&clock CMGP02_USI>;
		clock-names = "gate_uart_clk4", "ipclk_uart4";
		status = "disabled";
	};

	/* USI_3_CMGP */
	serial_5: uart@11D60000 {
		compatible = "samsung,exynos-uart";
		samsung,separate-uart-clk;
		reg = <0x0 0x11D60000 0x100>;
		samsung,fifo-size = <64>;
		interrupts = <0 314 0>;
		pinctrl-names = "default";
		pinctrl-0 = <&uart5_bus_single>; /* or _bus_dual */
		samsung,usi-serial-v2;
		clocks = <&clock GATE_USI_CMGP03_QCH>, <&clock CMGP03_USI>;
		clock-names = "gate_uart_clk5", "ipclk_uart5";
		status = "disabled";
	};

	/* USI_4_CMGP */
	serial_6: uart@11D80000 {
		compatible = "samsung,exynos-uart";
		samsung,separate-uart-clk;
		reg = <0x0 0x11D80000 0x100>;
		samsung,fifo-size = <64>;
		interrupts = <0 315 0>;
		pinctrl-names = "default";
		pinctrl-0 = <&uart6_bus_single>; /* or _bus_dual */
		samsung,usi-serial-v2;
		clocks = <&clock GATE_USI_CMGP04_QCH>, <&clock CMGP04_USI>;
		clock-names = "gate_uart_clk6", "ipclk_uart6";
		status = "disabled";
	};

	/* USI_PERI_USI_0 */
	serial_7: uart@13920000 {
		compatible = "samsung,exynos-uart";
		samsung,separate-uart-clk;
		reg = <0x0 0x13920000 0x100>;
		samsung,fifo-size = <64>;
		interrupts = <0 267 0>;
		pinctrl-names = "default";
		pinctrl-0 = <&uart7_bus_single>; /* or _bus_dual */
		samsung,usi-serial-v2;
		clocks = <&clock GATE_USI00_USI_QCH>, <&clock USI_USI>;
		clock-names = "gate_uart_clk7", "ipclk_uart7";
		status = "disabled";
	};

	/* I2C_0 */
	i2c_0: i2c@13830000 {
		compatible = "samsung,s3c2440-i2c";
		reg = <0x0 0x13830000 0x100>;
		interrupts = <0 247 0>;
		#address-cells = <1>;
		#size-cells = <0>;
		pinctrl-names = "default";
		pinctrl-0 = <&i2c0_bus>;
		clocks = <&clock GATE_I2C_0_QCH>, <&clock GATE_I2C_0_QCH>;
		clock-names = "rate_i2c", "gate_i2c";
		status = "disabled";
	};

	/* I2C_1 */
	i2c_1: i2c@13840000 {
		compatible = "samsung,s3c2440-i2c";
		reg = <0x0 0x13840000 0x100>;
		interrupts = <0 248 0>;
		#address-cells = <1>;
		#size-cells = <0>;
		pinctrl-names = "default";
		pinctrl-0 = <&i2c1_bus>;
		clocks = <&clock GATE_I2C_1_QCH>, <&clock GATE_I2C_1_QCH>;
		clock-names = "rate_i2c", "gate_i2c";
		status = "disabled";
	};

	/* I2C_2 */
	i2c_2: i2c@13850000 {
		compatible = "samsung,s3c2440-i2c";
		reg = <0x0 0x13850000 0x100>;
		interrupts = <0 249 0>;
		#address-cells = <1>;
		#size-cells = <0>;
		pinctrl-names = "default";
		pinctrl-0 = <&i2c2_bus>;
		clocks = <&clock GATE_I2C_2_QCH>, <&clock GATE_I2C_2_QCH>;
		clock-names = "rate_i2c", "gate_i2c";
		status = "disabled";
	};

	/* I2C_3 */
	i2c_3: i2c@13860000 {
		compatible = "samsung,s3c2440-i2c";
		reg = <0x0 0x13860000 0x100>;
		interrupts = <0 250 0>;
		#address-cells = <1>;
		#size-cells = <0>;
		pinctrl-names = "default";
		pinctrl-0 = <&i2c3_bus>;
		clocks = <&clock GATE_I2C_3_QCH>, <&clock GATE_I2C_3_QCH>;
		clock-names = "rate_i2c", "gate_i2c";
		status = "disabled";
	};

	/* I2C_4 */
	i2c_4: i2c@13870000 {
		compatible = "samsung,s3c2440-i2c";
		reg = <0x0 0x13870000 0x100>;
		interrupts = <0 251 0>;
		#address-cells = <1>;
		#size-cells = <0>;
		pinctrl-names = "default";
		pinctrl-0 = <&i2c4_bus>;
		clocks = <&clock GATE_I2C_4_QCH>, <&clock GATE_I2C_4_QCH>;
		clock-names = "rate_i2c", "gate_i2c";
		status = "disabled";
	};

	/* I2C_5 */
	i2c_5: i2c@13880000 {
		compatible = "samsung,s3c2440-i2c";
		reg = <0x0 0x13880000 0x100>;
		interrupts = <0 252 0>;
		#address-cells = <1>;
		#size-cells = <0>;
		pinctrl-names = "default";
		pinctrl-0 = <&i2c5_bus>;
		clocks = <&clock GATE_I2C_5_QCH>, <&clock GATE_I2C_5_QCH>;
		clock-names = "rate_i2c", "gate_i2c";
		status = "disabled";
	};

	/* I2C_6 */
	i2c_6: i2c@13890000 {
		compatible = "samsung,s3c2440-i2c";
		reg = <0x0 0x13890000 0x100>;
		interrupts = <0 253 0>;
		#address-cells = <1>;
		#size-cells = <0>;
		pinctrl-names = "default";
		pinctrl-0 = <&i2c6_bus>;
		clocks = <&clock GATE_I2C_6_QCH>, <&clock GATE_I2C_6_QCH>;
		clock-names = "rate_i2c", "gate_i2c";
		status = "disabled";
	};

	ufs: ufs@0x13520000 {
		/* ----------------------- */
		/* 1. SYSTEM CONFIGURATION */
		/* ----------------------- */
		compatible ="samsung,exynos-ufs";
		#address-cells = <2>;
		#size-cells = <1>;
		ranges;
		reg =
			<0x0 0x13520000 0x200>,	/* 0: HCI standard */
			<0x0 0x13521100 0x200>,	/* 1: Vendor specificed */
			<0x0 0x13510000 0x8000>,	/* 2: UNIPRO */
			<0x0 0x13530000 0x100>;	/* 3: UFS protector */
		interrupts = <0 157 0>;
		pinctrl-names = "default";
		pinctrl-0 = <&ufs_rst_n &ufs_refclk_out>;
		clocks =
			/* aclk clock */
			<&clock GATE_UFS_EMBD_QCH_UFS>,
			/* unipro clocks */
			<&clock UFS_EMBD>;

		clock-names =
			/* aclk clocks */
			"GATE_UFS_EMBD_QCH_UFS",
			/* unipro clocks */
			"UFS_EMBD";

		/* PM QoS for INT power domain */
/*		ufs-pm-qos-int = <400000>;*/

		/* DMA coherent callback, should be coupled with 'ufs-sys' */
		dma-coherent;

		/* UFS PHY isolation and TCXO control */
		samsung,pmu-phandle = <&pmu_system_controller>;

		/* TCXO exclusive control  */
		tcxo-ex-ctrl = <0>;

		/* UFS IO coherency  */
		samsung,sysreg-fsys-phandle = <&sysreg_fsys_system_controller>;

		/* ----------------------- */
		/* 2. UFS COMMON           */
		/* ----------------------- */
		freq-table-hz = <0 0>, <0 0>;

		vcc-supply = <&ufs_fixed_vcc>;
		vcc-fixed-regulator;


		/* ----------------------- */
		/* 3. UFS EXYNOS           */
		/* ----------------------- */
		hw-rev = <UFS_VER_0005>;

		/* power mode change */
		ufs,pmd-attr-lane = /bits/ 8 <1>;
		ufs,pmd-attr-gear = /bits/ 8 <3>;

		/* hiberantion */
		ufs-rx-min-activate-time-cap = <3>;
		ufs-rx-hibern8-time-cap = <2>;
		ufs-tx-hibern8-time-cap = <2>;

		/* board type for UFS CAL */
		brd-for-cal = <0>;

		fmp-id = <0>;
		smu-id = <0>;

		/* ----------------------- */
		/* 4. ADDITIONAL NODES     */
		/* ----------------------- */
		ufs-phy {
			#address-cells = <2>;
			#size-cells = <1>;
			ranges;
			reg = <0x0 0x13524000 0x800>;
		};

		ufs-dma-coherency {
			#address-cells = <2>;
			#size-cells = <1>;

			offset = <0x1010>;
			mask = <(BIT_8 | BIT_9)>;
			val = <(BIT_8 | BIT_9)>;
		};
	};

	ufs_fixed_vcc: fixedregulator@0 {
		       compatible = "regulator-fixed";
		       regulator-name = "ufs-vcc";
		       gpio = <&gpg4 0 0>;
		       regulator-boot-on;
		       enable-active-high;
	};

	exynos-pmu {
		compatible = "samsung,exynos-pmu";
		samsung,syscon-phandle = <&pmu_system_controller>;
	};

	pmu_system_controller: system-controller@11860000 {
		compatible = "samsung,exynos9610-pmu", "syscon";
		reg = <0x0 0x11860000 0x10000>;
	};

	exynos-sysreg-fsys {
		compatible = "samsung,exynos-sysreg-fsys";
		samsung,syscon-phandle = <&sysreg_fsys_system_controller>;
	};

	sysreg_fsys_system_controller: system-controller@13410000 {
		compatible = "samsung,exynos9610-sysreg-fsys", "syscon";
		reg = <0x0 0x13410000 0x1020>;
	};

	/* DMA */
	amba {
		#address-cells = <2>;
		#size-cells = <1>;
		compatible = "arm,amba-bus";
		interrupt-parent = <&gic>;
		ranges;

		pdma0: pdma0@120C0000 {
			compatible = "arm,pl330", "arm,primecell";
			reg = <0x0 0x120C0000 0x1000>;
			interrupts = <0 294 0>;
			clocks = <&clock GATE_PDMA_CORE_QCH>;
			clock-names = "apb_pclk";
			#dma-cells = <1>;
			#dma-channels = <8>;
			#dma-requests = <32>;
			#dma-multi-irq = <1>;
			dma-arwrapper = <0x120C4400>,
					<0x120C4420>,
					<0x120C4440>,
					<0x120C4460>,
					<0x120C4480>,
					<0x120C44A0>,
					<0x120C44C0>,
					<0x120C44E0>;
			dma-awwrapper = <0x120C4404>,
					<0x120C4424>,
					<0x120C4444>,
					<0x120C4464>,
					<0x120C4484>,
					<0x120C44A4>,
					<0x120C44C4>,
					<0x120C44E4>;
			dma-instwrapper = <0x120C4500>;
			dma-mask-bit = <36>;
			coherent-mask-bit = <36>;
		};
	};

	watchdog_cl0@10050000 {
		compatible = "samsung,exynos7-wdt";
		reg = <0x0 0x10050000 0x100>;
		interrupts = <0 232 0>;
		clocks = <&clock OSCCLK>, <&clock GATE_WDT_CLUSTER0_QCH>;
		clock-names = "rate_watchdog", "gate_watchdog";
		timeout-sec = <30>;
		samsung,syscon-phandle = <&pmu_system_controller>;
		index = <0>; /* if little cluster then index is 0*/
	};

	exynos_adc: adc@11C30000 {
		compatible = "samsung,exynos-adc-v3";
		reg = <0x0 0x11C30000 0x100>;
		sysreg = <0x11C10000>;
		interrupts = <0 271 0>;
		#io-channel-cells = <1>;
		io-channel-ranges;
		clocks = <&clock GATE_ADC_CMGP_QCH_S0>;
		clock-names = "gate_adcif";
	};

	rtc@11A20000 {
		compatible = "samsung,exynos8-rtc";
		reg = <0x0 0x11A20000 0x100>;
		interrupts = <0 29 0>, <0 30 0>;
		use-chub-only;
	};

	sec_pwm: pwm@13970000 {
		compatible = "samsung,s3c6400-pwm";
		reg = <0x0 0x13970000 0x1000>;
		samsung,pwm-outputs = <0>, <1>, <2>, <3>, <4>;
		#pwm-cells = <3>;
		clocks = <&clock GATE_PWM_MOTOR_QCH>, <&clock OSCCLK>;
		clock-names = "pwm_pclk", "pwm_sclk";
		status = "ok";
	};

	iommu-domain_dpu {
		compatible = "samsung,exynos-iommu-bus";
		#address-cells = <2>;
		#size-cells = <1>;
		ranges;

		domain-clients = <>;
	};

	iommu-domain_vipx {
		compatible = "samsung,exynos-iommu-bus";
		#address-cells = <2>;
		#size-cells = <1>;
		ranges;

		domain-clients = <>;
	};

	iommu-domain_abox {
		compatible = "samsung,exynos-iommu-bus";
		#address-cells = <2>;
		#size-cells = <1>;
		ranges;

		domain-clients = <>;
	};

	iommu-domain_isp {
		compatible = "samsung,exynos-iommu-bus";
		#address-cells = <2>;
		#size-cells = <1>;
		ranges;

		domain-clients = <>;
	};

	iommu-domain_mfc {
		compatible = "samsung,exynos-iommu-bus";
		#address-cells = <2>;
		#size-cells = <1>;
		ranges;

		domain-clients = <>;
	};

	iommu-domain_g2dmscljpeg {
		compatible = "samsung,exynos-iommu-bus";
		#address-cells = <2>;
		#size-cells = <1>;
		ranges;

		domain-clients = <>;
	};

	reboot {
		compatible = "exynos,reboot";
		pmu_base = <0x11860000>;
	};
};
